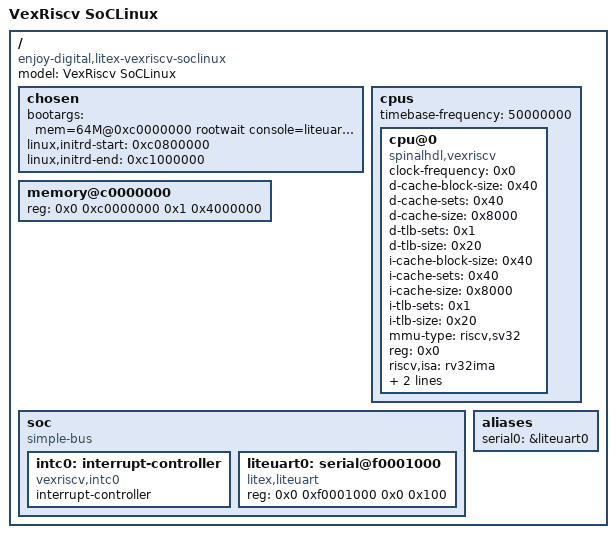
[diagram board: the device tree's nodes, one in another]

/dts-v1/;

/ {
	#address-cells = <0x2>;
	#size-cells = <0x2>;
	compatible = "enjoy-digital,litex-vexriscv-soclinux";
	model = "VexRiscv SoCLinux";

	chosen {
		bootargs = "mem=64M@0xc0000000 rootwait console=liteuart earlycon=sbi root=/dev/ram0 init=/sbin/init swiotlb=32";
		linux,initrd-start = <0xc0800000>;
		linux,initrd-end   = <0xc1000000>;
	};

	cpus {
		#address-cells = <0x1>;
		#size-cells = <0x0>;
		timebase-frequency = <50000000>;

		cpu@0 {
			clock-frequency = <0x0>;
			compatible = "spinalhdl,vexriscv", "sifive,rocket0", "riscv";
			d-cache-block-size = <0x40>;
			d-cache-sets = <0x40>;
			d-cache-size = <0x8000>;
			d-tlb-sets = <0x1>;
			d-tlb-size = <0x20>;
			device_type = "cpu";
			i-cache-block-size = <0x40>;
			i-cache-sets = <0x40>;
			i-cache-size = <0x8000>;
			i-tlb-sets = <0x1>;
			i-tlb-size = <0x20>;
			mmu-type = "riscv,sv32";
			reg = <0x0>;
			riscv,isa = "rv32ima";
			sifive,itim = <0x1>;
			status = "okay";
			tlb-split;
		};
	};

	memory@c0000000 {
		device_type = "memory";
		reg = <0x0 0xc0000000 0x1 0x4000000>;
	};

	soc {
		#address-cells = <0x2>;
		#size-cells = <0x2>;
		compatible = "simple-bus";
		ranges;

		intc0: interrupt-controller {
			interrupt-controller;
			#interrupt-cells = <1>;
			compatible = "vexriscv,intc0";
			status = "okay";
		};

		liteuart0: serial@f0001000 {
			device_type = "serial";
			compatible = "litex,liteuart";
			reg = <0x0 0xf0001000 0x0 0x100>;
			status = "okay";
		};
	
	};

	aliases {

	   serial0 = &liteuart0;

	};

};

